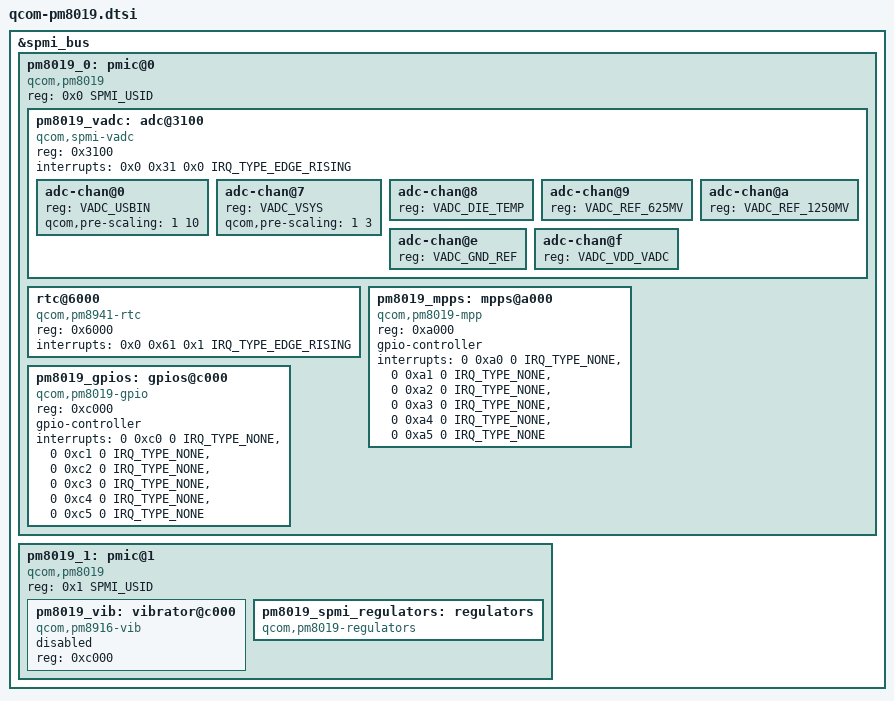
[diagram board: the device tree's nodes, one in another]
// SPDX-License-Identifier: BSD-3-Clause
/*
 * Copyright (c) 2021, Konrad Dybcio
 */
#include <dt-bindings/iio/qcom,spmi-vadc.h>
#include <dt-bindings/interrupt-controller/irq.h>
#include <dt-bindings/spmi/spmi.h>

&spmi_bus {

	pm8019_0: pmic@0 {
		compatible = "qcom,pm8019", "qcom,spmi-pmic";
		reg = <0x0 SPMI_USID>;
		#address-cells = <1>;
		#size-cells = <0>;

		pm8019_vadc: adc@3100 {
			compatible = "qcom,spmi-vadc";
			reg = <0x3100>;
			interrupts = <0x0 0x31 0x0 IRQ_TYPE_EDGE_RISING>;
			#address-cells = <1>;
			#size-cells = <0>;
			#io-channel-cells = <1>;

			adc-chan@0 {
				reg = <VADC_USBIN>;
				qcom,pre-scaling = <1 10>;
			};
			adc-chan@7 {
				reg = <VADC_VSYS>;
				qcom,pre-scaling = <1 3>;
			};
			adc-chan@8 {
				reg = <VADC_DIE_TEMP>;
			};
			adc-chan@9 {
				reg = <VADC_REF_625MV>;
			};
			adc-chan@a {
				reg = <VADC_REF_1250MV>;
			};
			adc-chan@e {
				reg = <VADC_GND_REF>;
			};
			adc-chan@f {
				reg = <VADC_VDD_VADC>;
			};
		};

		rtc@6000 {
			compatible = "qcom,pm8941-rtc";
			reg = <0x6000>;
			reg-names = "rtc", "alarm";
			interrupts = <0x0 0x61 0x1 IRQ_TYPE_EDGE_RISING>;
		};

		pm8019_mpps: mpps@a000 {
			compatible = "qcom,pm8019-mpp";
			reg = <0xa000>;
			gpio-controller;
			#gpio-cells = <2>;
			interrupts = <0 0xa0 0 IRQ_TYPE_NONE>,
				     <0 0xa1 0 IRQ_TYPE_NONE>,
				     <0 0xa2 0 IRQ_TYPE_NONE>,
				     <0 0xa3 0 IRQ_TYPE_NONE>,
					 <0 0xa4 0 IRQ_TYPE_NONE>,
					 <0 0xa5 0 IRQ_TYPE_NONE>;
		};

		pm8019_gpios: gpios@c000 {
			compatible = "qcom,pm8019-gpio";
			reg = <0xc000>;
			gpio-controller;
			#gpio-cells = <2>;
			interrupts = <0 0xc0 0 IRQ_TYPE_NONE>,
				     <0 0xc1 0 IRQ_TYPE_NONE>,
				     <0 0xc2 0 IRQ_TYPE_NONE>,
				     <0 0xc3 0 IRQ_TYPE_NONE>,
					 <0 0xc4 0 IRQ_TYPE_NONE>,
					 <0 0xc5 0 IRQ_TYPE_NONE>;
		};
	};

	pm8019_1: pmic@1 {
		compatible = "qcom,pm8019", "qcom,spmi-pmic";
		reg = <0x1 SPMI_USID>;
		#address-cells = <1>;
		#size-cells = <0>;

		pm8019_vib: vibrator@c000 {
			compatible = "qcom,pm8916-vib";
			reg = <0xc000>;
			status = "disabled";
		};

		pm8019_spmi_regulators: regulators {
			compatible = "qcom,pm8019-regulators";
		};
	};
};
